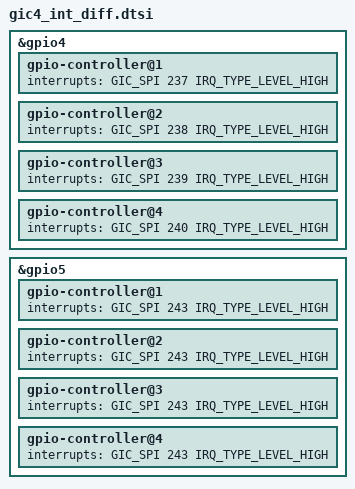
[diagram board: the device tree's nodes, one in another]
/**
 * Semidrive GIC4-GIC5 INT DIFF DTS file
 *
 * Copyright (C) 2019, Semidrive Semiconductor
 *
 * All rights reserved.
 */

/**
 * This file is maintained by Semidrive. This file contains the gic4 int
 different with gic5
 */

#include <dt-bindings/interrupt-controller/arm-gic.h>

&gpio4 {
    gpio-controller@1 {
        interrupts = <GIC_SPI 237 IRQ_TYPE_LEVEL_HIGH>;
    };
    gpio-controller@2 {
        interrupts = <GIC_SPI 238 IRQ_TYPE_LEVEL_HIGH>;
    };
    gpio-controller@3 {
        interrupts = <GIC_SPI 239 IRQ_TYPE_LEVEL_HIGH>;
    };
    gpio-controller@4 {
        interrupts = <GIC_SPI 240 IRQ_TYPE_LEVEL_HIGH>;
    };
};

&gpio5 {
    gpio-controller@1 {
        interrupts = <GIC_SPI 243 IRQ_TYPE_LEVEL_HIGH>;
    };
    gpio-controller@2 {
        interrupts = <GIC_SPI 243 IRQ_TYPE_LEVEL_HIGH>;
    };
    gpio-controller@3 {
        interrupts = <GIC_SPI 243 IRQ_TYPE_LEVEL_HIGH>;
    };
    gpio-controller@4 {
        interrupts = <GIC_SPI 243 IRQ_TYPE_LEVEL_HIGH>;
    };
};
